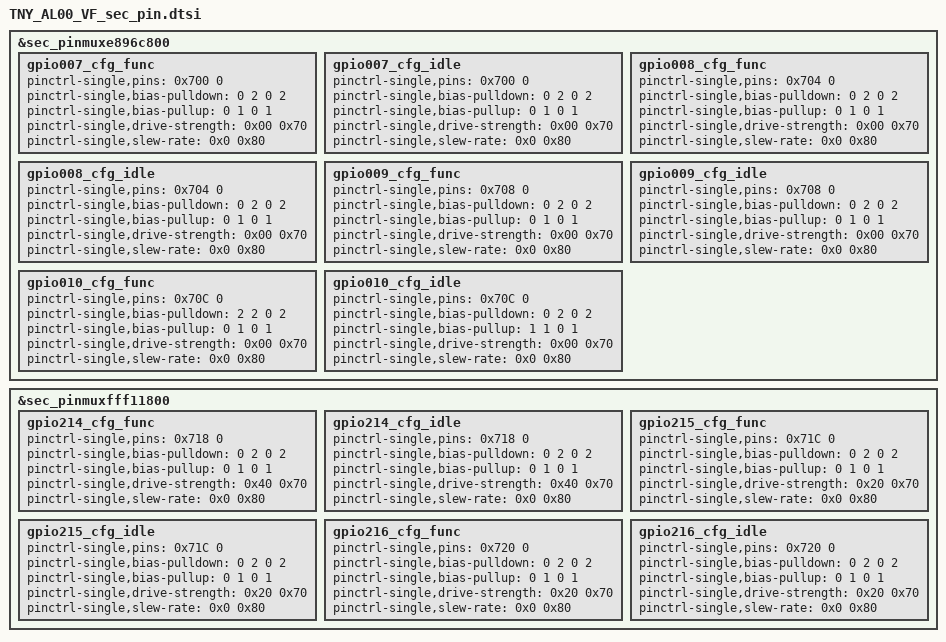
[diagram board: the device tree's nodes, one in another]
    &sec_pinmuxe896c800 {
		gpio007_cfg_func {
                     pinctrl-single,pins = <0x700  0>;
                     pinctrl-single,bias-pulldown = <0 2 0 2>;
                     pinctrl-single,bias-pullup = <0 1 0 1>;
                     pinctrl-single,drive-strength = <0x00 0x70>;
                     pinctrl-single,slew-rate = <0x0 0x80>;
		};
		gpio007_cfg_idle {
                     pinctrl-single,pins = <0x700  0>;
                     pinctrl-single,bias-pulldown = <0 2 0 2>;
                     pinctrl-single,bias-pullup = <0 1 0 1>;
                     pinctrl-single,drive-strength = <0x00 0x70>;
                     pinctrl-single,slew-rate = <0x0 0x80>;
		};

		gpio008_cfg_func {
                     pinctrl-single,pins = <0x704  0>;
                     pinctrl-single,bias-pulldown = <0 2 0 2>;
                     pinctrl-single,bias-pullup = <0 1 0 1>;
                     pinctrl-single,drive-strength = <0x00 0x70>;
                     pinctrl-single,slew-rate = <0x0 0x80>;
		};
		gpio008_cfg_idle {
                     pinctrl-single,pins = <0x704  0>;
                     pinctrl-single,bias-pulldown = <0 2 0 2>;
                     pinctrl-single,bias-pullup = <0 1 0 1>;
                     pinctrl-single,drive-strength = <0x00 0x70>;
                     pinctrl-single,slew-rate = <0x0 0x80>;
		};

		gpio009_cfg_func {
                     pinctrl-single,pins = <0x708  0>;
                     pinctrl-single,bias-pulldown = <0 2 0 2>;
                     pinctrl-single,bias-pullup = <0 1 0 1>;
                     pinctrl-single,drive-strength = <0x00 0x70>;
                     pinctrl-single,slew-rate = <0x0 0x80>;
		};
		gpio009_cfg_idle {
                     pinctrl-single,pins = <0x708  0>;
                     pinctrl-single,bias-pulldown = <0 2 0 2>;
                     pinctrl-single,bias-pullup = <0 1 0 1>;
                     pinctrl-single,drive-strength = <0x00 0x70>;
                     pinctrl-single,slew-rate = <0x0 0x80>;
		};

		gpio010_cfg_func {
                     pinctrl-single,pins = <0x70C  0>;
                     pinctrl-single,bias-pulldown = <2 2 0 2>;
                     pinctrl-single,bias-pullup = <0 1 0 1>;
                     pinctrl-single,drive-strength = <0x00 0x70>;
                     pinctrl-single,slew-rate = <0x0 0x80>;
		};
		gpio010_cfg_idle {
                     pinctrl-single,pins = <0x70C  0>;
                     pinctrl-single,bias-pulldown = <0 2 0 2>;
                     pinctrl-single,bias-pullup = <1 1 0 1>;
                     pinctrl-single,drive-strength = <0x00 0x70>;
                     pinctrl-single,slew-rate = <0x0 0x80>;
		};

    };

    &sec_pinmuxfff11800 {
		gpio214_cfg_func {
                     pinctrl-single,pins = <0x718  0>;
                     pinctrl-single,bias-pulldown = <0 2 0 2>;
                     pinctrl-single,bias-pullup = <0 1 0 1>;
                     pinctrl-single,drive-strength = <0x40 0x70>;
                     pinctrl-single,slew-rate = <0x0 0x80>;
		};
		gpio214_cfg_idle {
                     pinctrl-single,pins = <0x718  0>;
                     pinctrl-single,bias-pulldown = <0 2 0 2>;
                     pinctrl-single,bias-pullup = <0 1 0 1>;
                     pinctrl-single,drive-strength = <0x40 0x70>;
                     pinctrl-single,slew-rate = <0x0 0x80>;
		};

		gpio215_cfg_func {
                     pinctrl-single,pins = <0x71C  0>;
                     pinctrl-single,bias-pulldown = <0 2 0 2>;
                     pinctrl-single,bias-pullup = <0 1 0 1>;
                     pinctrl-single,drive-strength = <0x20 0x70>;
                     pinctrl-single,slew-rate = <0x0 0x80>;
		};
		gpio215_cfg_idle {
                     pinctrl-single,pins = <0x71C  0>;
                     pinctrl-single,bias-pulldown = <0 2 0 2>;
                     pinctrl-single,bias-pullup = <0 1 0 1>;
                     pinctrl-single,drive-strength = <0x20 0x70>;
                     pinctrl-single,slew-rate = <0x0 0x80>;
		};

		gpio216_cfg_func {
                     pinctrl-single,pins = <0x720  0>;
                     pinctrl-single,bias-pulldown = <0 2 0 2>;
                     pinctrl-single,bias-pullup = <0 1 0 1>;
                     pinctrl-single,drive-strength = <0x20 0x70>;
                     pinctrl-single,slew-rate = <0x0 0x80>;
		};
		gpio216_cfg_idle {
                     pinctrl-single,pins = <0x720  0>;
                     pinctrl-single,bias-pulldown = <0 2 0 2>;
                     pinctrl-single,bias-pullup = <0 1 0 1>;
                     pinctrl-single,drive-strength = <0x20 0x70>;
                     pinctrl-single,slew-rate = <0x0 0x80>;
		};

    };

